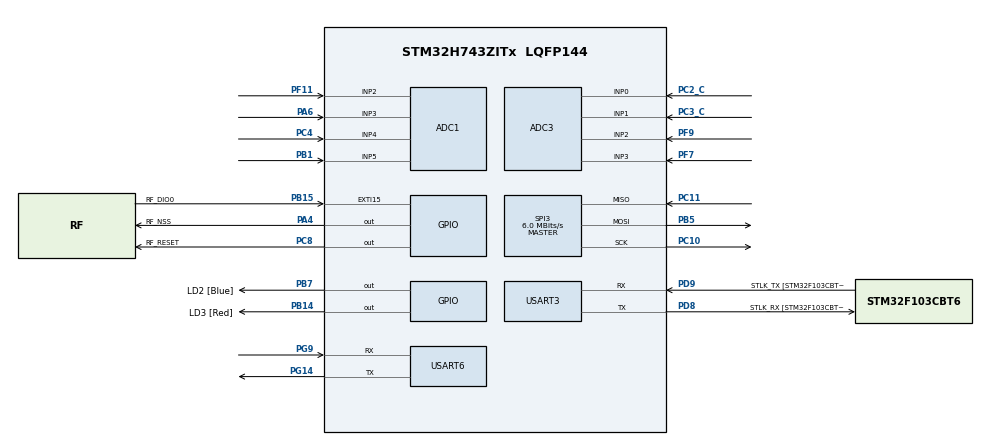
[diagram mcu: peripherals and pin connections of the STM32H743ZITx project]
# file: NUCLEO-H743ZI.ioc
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ADC1.Channel-2\#ChannelRegularConversion=ADC_CHANNEL_2
ADC1.NbrOfConversionFlag=1
ADC1.OffsetNumber-2\#ChannelRegularConversion=ADC_OFFSET_NONE
ADC1.Rank-2\#ChannelRegularConversion=1
ADC1.SamplingTime-2\#ChannelRegularConversion=ADC_SAMPLETIME_1CYCLE_5
ADC1.master=1
ADC3.Channel-0\#ChannelRegularConversion=ADC_CHANNEL_0
ADC3.NbrOfConversionFlag=1
ADC3.OffsetNumber-0\#ChannelRegularConversion=ADC_OFFSET_NONE
ADC3.Rank-0\#ChannelRegularConversion=1
ADC3.SamplingTime-0\#ChannelRegularConversion=ADC_SAMPLETIME_1CYCLE_5
FREERTOS.Tasks01=defaultTask,0,512,MAIN_taskEntry,As weak,NULL,Dynamic,NULL,NULL
FREERTOS.configMINIMAL_STACK_SIZE=256
FREERTOS.configTOTAL_HEAP_SIZE=32768
FREERTOS.configUSE_TIMERS=1
Mcu.Family=STM32H7
Mcu.Name=STM32H743ZITx
Mcu.Package=LQFP144
NVIC.EXTI15_10_IRQn=true\:5\:0\:false\:false\:true\:true\:true\:true
NVIC.PriorityGroup=NVIC_PRIORITYGROUP_4
NVIC.TIM1_UP_IRQn=true\:0\:0\:false\:false\:true\:false\:false\:true
NVIC.TimeBase=TIM1_UP_IRQn
NVIC.TimeBaseIP=TIM1
PA13\ (JTMS/SWDIO).GPIO_Label=TMS
PA13\ (JTMS/SWDIO).Mode=Serial_Wire
PA13\ (JTMS/SWDIO).Signal=SYS_JTMS-SWDIO
PA14\ (JTCK/SWCLK).GPIO_Label=TCK
PA14\ (JTCK/SWCLK).Mode=Serial_Wire
PA14\ (JTCK/SWCLK).Signal=SYS_JTCK-SWCLK
PA4.GPIO_Label=RF_NSS
PA4.Signal=GPIO_Output
PA6.Signal=ADCx_INP3
PB1.Signal=ADCx_INP5
PB14.GPIO_Label=LD3 [Red]
PB14.Signal=GPIO_Output
PB15.GPIO_Label=RF_DIO0
PB15.Signal=GPXTI15
PB3\ (JTDO/TRACESWO).Signal=SYS_JTDO-SWO
PB5.Mode=Full_Duplex_Master
PB5.Signal=SPI3_MOSI
PB7.GPIO_Label=LD2 [Blue]
PB7.Signal=GPIO_Output
PC10.Mode=Full_Duplex_Master
PC10.Signal=SPI3_SCK
PC11.Mode=Full_Duplex_Master
PC11.Signal=SPI3_MISO
PC14-OSC32_IN\ (OSC32_IN).Mode=LSE-External-Oscillator
PC14-OSC32_IN\ (OSC32_IN).Signal=RCC_OSC32_IN
PC15-OSC32_OUT\ (OSC32_OUT).Mode=LSE-External-Oscillator
PC15-OSC32_OUT\ (OSC32_OUT).Signal=RCC_OSC32_OUT
PC2_C.Mode=IN0-Single-Ended
PC2_C.Signal=ADC3_INP0
PC3_C.Mode=IN1-Single-Ended
PC3_C.Signal=ADC3_INP1
PC4.Signal=ADCx_INP4
PC8.GPIO_Label=RF_RESET
PC8.Signal=GPIO_Output
PD8.GPIO_Label=STLK_RX [STM32F103CBT6_PA3]
PD8.Mode=Asynchronous
PD8.Signal=USART3_TX
PD9.GPIO_Label=STLK_TX [STM32F103CBT6_PA2]
PD9.Mode=Asynchronous
PD9.Signal=USART3_RX
PF11.Mode=IN2-Single-Ended
PF11.Signal=ADC1_INP2
PF7.Mode=IN3-Single-Ended
PF7.Signal=ADC3_INP3
PF9.Mode=IN2-Single-Ended
PF9.Signal=ADC3_INP2
PG14.Mode=Asynchronous
PG14.Signal=USART6_TX
PG9.Mode=Asynchronous
PG9.Signal=USART6_RX
PH0-OSC_IN\ (PH0).GPIO_Label=MCO
PH0-OSC_IN\ (PH0).Mode=HSE-External-Clock-Source
PH0-OSC_IN\ (PH0).Signal=RCC_OSC_IN
PH1-OSC_OUT\ (PH1).Mode=HSE-External-Clock-Source
PH1-OSC_OUT\ (PH1).Signal=RCC_OSC_OUT
ProjectManager.HeapSize=0x200
ProjectManager.StackSize=0x400
ProjectManager.TargetToolchain=EWARM V8
RCC.48MHZClocksFreq_Value=24000000
RCC.ADCFreq_Value=76000000
RCC.AHBFreq_Value=216000000
RCC.APB1CLKDivider=RCC_HCLK_DIV4
RCC.APB1Freq_Value=96000000
RCC.APB1TimFreq_Value=108000000
RCC.APB2CLKDivider=RCC_HCLK_DIV2
RCC.APB2Freq_Value=96000000
RCC.APB2TimFreq_Value=216000000
RCC.APB3Freq_Value=96000000
RCC.APB4Freq_Value=96000000
RCC.CortexFreq_Value=96000000
RCC.DIVM1=1
RCC.DIVM2=1
RCC.DIVN1=24
RCC.DIVN2=19
RCC.DIVQ1=4
RCC.HCLKFreq_Value=96000000
RCC.HSE_VALUE=8000000
RCC.HSI_VALUE=64000000
RCC.PLLM=25
RCC.PLLMUL=RCC_PLL_MUL9
RCC.PLLN=432
RCC.PLLQ=9
RCC.PLLSourceVirtual=RCC_PLLSOURCE_HSE
RCC.PRESCALERUSB=RCC_USBCLKSOURCE_PLL_DIV1_5
RCC.PWR_Regulator_Voltage_Scale=PWR_REGULATOR_VOLTAGE_SCALE1
RCC.SYSCLKFreq_VALUE=96000000
RCC.SYSCLKSource=RCC_SYSCLKSOURCE_PLLCLK
RCC.SYSCLKSourceVirtual=RCC_SYSCLKSOURCE_PLLCLK
RCC.USBFreq_Value=48000000
RCC.VCOOutputFreq_Value=432000000
SH.ADCx_INP3.0=ADC1_INP3,IN3-Single-Ended
SH.ADCx_INP4.0=ADC1_INP4,IN4-Single-Ended
SH.ADCx_INP5.0=ADC1_INP5,IN5-Single-Ended
SPI3.BaudRatePrescaler=SPI_BAUDRATEPRESCALER_8
SPI3.CalculateBaudRate=6.0 MBits/s
SPI3.DataSize=SPI_DATASIZE_8BIT
SPI3.Direction=SPI_DIRECTION_2LINES
SPI3.Mode=SPI_MODE_MASTER
SPI3.VirtualType=VM_MASTER
USART3.VirtualMode-Asynchronous=VM_ASYNC
USART6.VirtualMode-Asynchronous=VM_ASYNC
VP_FREERTOS_VS_CMSIS_V1.Mode=CMSIS_V1
VP_RTC_VS_RTC_Activate.Mode=RTC_Enabled
VP_SYS_VS_tim1.Mode=TIM1
VP_SYS_V_PVD_IN.Mode=Mode_PVD_Int
board=NUCLEO-H743ZI

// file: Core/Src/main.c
/* USER CODE BEGIN Header */
/**
  ******************************************************************************
  * @file           : main.c
  * @brief          : Main program body
  ******************************************************************************
  * @attention
  *
  * <h2><center>&copy; Copyright (c) 2019 STMicroelectronics.
  * All rights reserved.</center></h2>
  *
  * This software component is licensed by ST under Ultimate Liberty license
  * SLA0044, the "License"; You may not use this file except in compliance with
  * the License. You may obtain a copy of the License at:
  *                             www.st.com/SLA0044
  *
  ******************************************************************************
  */
/* USER CODE END Header */

#include "main.h"
#include "cmsis_os.h"

/* USER CODE BEGIN Includes */
#include "config.h"
/* USER CODE END Includes */

ADC_HandleTypeDef hadc1;
ADC_HandleTypeDef hadc3;

RTC_HandleTypeDef hrtc;

SPI_HandleTypeDef hspi3;

UART_HandleTypeDef huart3;
UART_HandleTypeDef huart6;

osThreadId defaultTaskHandle;
/* USER CODE BEGIN PV */
/* Private variables ---------------------------------------------------------*/

/* USER CODE END PV */

void SystemClock_Config(void);
static void MX_GPIO_Init(void);
static void MX_USART3_UART_Init(void);
static void MX_USART6_UART_Init(void);
static void MX_ADC3_Init(void);
static void MX_ADC1_Init(void);
static void MX_RTC_Init(void);
static void MX_SPI3_Init(void);
void MAIN_taskEntry(void const * argument);

/* USER CODE BEGIN PFP */
/* Private function prototypes -----------------------------------------------*/

/* USER CODE END PFP */

int main(void)
{

  /* MCU Configuration--------------------------------------------------------*/

  /* Reset of all peripherals, Initializes the Flash interface and the Systick. */
  HAL_Init();

  /* Configure the system clock */
  SystemClock_Config();

  /* Initialize all configured peripherals */
  MX_GPIO_Init();
  MX_USART3_UART_Init();
  MX_USART6_UART_Init();
  MX_ADC3_Init();
  MX_ADC1_Init();
  MX_RTC_Init();
  MX_SPI3_Init();
  /* USER CODE BEGIN 2 */
  RF_init(&hspi3);

  /* USER CODE END 2 */

  /* Create the thread(s) */
  /* definition and creation of defaultTask */
  osThreadDef(defaultTask, MAIN_taskEntry, osPriorityNormal, 0, 512);
  defaultTaskHandle = osThreadCreate(osThread(defaultTask), NULL);

  /* Start scheduler */
  osKernelStart();

  /* We should never get here as control is now taken by the scheduler */

  /* Infinite loop */
  while (1)
  {

  }
}

void SystemClock_Config(void)
{
  RCC_OscInitTypeDef RCC_OscInitStruct = {0};
  RCC_ClkInitTypeDef RCC_ClkInitStruct = {0};
  RCC_PeriphCLKInitTypeDef PeriphClkInitStruct = {0};

  /** Supply configuration update enable
  */
  MODIFY_REG(PWR->CR3, PWR_CR3_SCUEN, 0);
  /** Configure the main internal regulator output voltage
  */
  __HAL_PWR_VOLTAGESCALING_CONFIG(PWR_REGULATOR_VOLTAGE_SCALE1);

  while ((PWR->D3CR & (PWR_D3CR_VOSRDY)) != PWR_D3CR_VOSRDY)
  {

  }
  /** Macro to configure the PLL clock source
  */
  __HAL_RCC_PLL_PLLSOURCE_CONFIG(RCC_PLLSOURCE_HSE);
  /** Initializes the CPU, AHB and APB busses clocks
  */
  RCC_OscInitStruct.OscillatorType = RCC_OSCILLATORTYPE_LSI|RCC_OSCILLATORTYPE_HSE;
  RCC_OscInitStruct.HSEState = RCC_HSE_BYPASS;
  RCC_OscInitStruct.LSIState = RCC_LSI_ON;
  RCC_OscInitStruct.PLL.PLLState = RCC_PLL_ON;
  RCC_OscInitStruct.PLL.PLLSource = RCC_PLLSOURCE_HSE;
  RCC_OscInitStruct.PLL.PLLM = 1;
  RCC_OscInitStruct.PLL.PLLN = 24;
  RCC_OscInitStruct.PLL.PLLP = 2;
  RCC_OscInitStruct.PLL.PLLQ = 4;
  RCC_OscInitStruct.PLL.PLLR = 2;
  RCC_OscInitStruct.PLL.PLLRGE = RCC_PLL1VCIRANGE_3;
  RCC_OscInitStruct.PLL.PLLVCOSEL = RCC_PLL1VCOWIDE;
  RCC_OscInitStruct.PLL.PLLFRACN = 0;
  if (HAL_RCC_OscConfig(&RCC_OscInitStruct) != HAL_OK)
  {
    Error_Handler();
  }
  /** Initializes the CPU, AHB and APB busses clocks
  */
  RCC_ClkInitStruct.ClockType = RCC_CLOCKTYPE_HCLK|RCC_CLOCKTYPE_SYSCLK
                              |RCC_CLOCKTYPE_PCLK1|RCC_CLOCKTYPE_PCLK2
                              |RCC_CLOCKTYPE_D3PCLK1|RCC_CLOCKTYPE_D1PCLK1;
  RCC_ClkInitStruct.SYSCLKSource = RCC_SYSCLKSOURCE_PLLCLK;
  RCC_ClkInitStruct.SYSCLKDivider = RCC_SYSCLK_DIV1;
  RCC_ClkInitStruct.AHBCLKDivider = RCC_HCLK_DIV1;
  RCC_ClkInitStruct.APB3CLKDivider = RCC_APB3_DIV1;
  RCC_ClkInitStruct.APB1CLKDivider = RCC_APB1_DIV1;
  RCC_ClkInitStruct.APB2CLKDivider = RCC_APB2_DIV1;
  RCC_ClkInitStruct.APB4CLKDivider = RCC_APB4_DIV1;

  if (HAL_RCC_ClockConfig(&RCC_ClkInitStruct, FLASH_LATENCY_1) != HAL_OK)
  {
    Error_Handler();
  }
  PeriphClkInitStruct.PeriphClockSelection = RCC_PERIPHCLK_RTC|RCC_PERIPHCLK_USART3
                              |RCC_PERIPHCLK_USART6|RCC_PERIPHCLK_SPI3
                              |RCC_PERIPHCLK_ADC;
  PeriphClkInitStruct.PLL2.PLL2M = 1;
  PeriphClkInitStruct.PLL2.PLL2N = 19;
  PeriphClkInitStruct.PLL2.PLL2P = 2;
  PeriphClkInitStruct.PLL2.PLL2Q = 2;
  PeriphClkInitStruct.PLL2.PLL2R = 2;
  PeriphClkInitStruct.PLL2.PLL2RGE = RCC_PLL2VCIRANGE_3;
  PeriphClkInitStruct.PLL2.PLL2VCOSEL = RCC_PLL2VCOMEDIUM;
  PeriphClkInitStruct.PLL2.PLL2FRACN = 0;
  PeriphClkInitStruct.Spi123ClockSelection = RCC_SPI123CLKSOURCE_PLL;
  PeriphClkInitStruct.Usart234578ClockSelection = RCC_USART234578CLKSOURCE_D2PCLK1;
  PeriphClkInitStruct.Usart16ClockSelection = RCC_USART16CLKSOURCE_D2PCLK2;
  PeriphClkInitStruct.AdcClockSelection = RCC_ADCCLKSOURCE_PLL2;
  PeriphClkInitStruct.RTCClockSelection = RCC_RTCCLKSOURCE_LSI;
  if (HAL_RCCEx_PeriphCLKConfig(&PeriphClkInitStruct) != HAL_OK)
  {
    Error_Handler();
  }
}

static void MX_ADC1_Init(void)
{

  ADC_MultiModeTypeDef multimode = {0};
  ADC_ChannelConfTypeDef sConfig = {0};

  /** Common config
  */
  hadc1.Instance = ADC1;
  hadc1.Init.ClockPrescaler = ADC_CLOCK_ASYNC_DIV4;
  hadc1.Init.Resolution = ADC_RESOLUTION_16B;
  hadc1.Init.ScanConvMode = ADC_SCAN_DISABLE;
  hadc1.Init.EOCSelection = ADC_EOC_SINGLE_CONV;
  hadc1.Init.LowPowerAutoWait = DISABLE;
  hadc1.Init.ContinuousConvMode = DISABLE;
  hadc1.Init.NbrOfConversion = 1;
  hadc1.Init.DiscontinuousConvMode = DISABLE;
  hadc1.Init.ExternalTrigConv = ADC_SOFTWARE_START;
  hadc1.Init.ExternalTrigConvEdge = ADC_EXTERNALTRIGCONVEDGE_NONE;
  hadc1.Init.ConversionDataManagement = ADC_CONVERSIONDATA_DR;
  hadc1.Init.Overrun = ADC_OVR_DATA_PRESERVED;
  hadc1.Init.LeftBitShift = ADC_LEFTBITSHIFT_NONE;
  hadc1.Init.BoostMode = DISABLE;
  hadc1.Init.OversamplingMode = DISABLE;
  if (HAL_ADC_Init(&hadc1) != HAL_OK)
  {
    Error_Handler();
  }
  /** Configure the ADC multi-mode
  */
  multimode.Mode = ADC_MODE_INDEPENDENT;
  if (HAL_ADCEx_MultiModeConfigChannel(&hadc1, &multimode) != HAL_OK)
  {
    Error_Handler();
  }
  /** Configure Regular Channel
  */
  sConfig.Channel = ADC_CHANNEL_2;
  sConfig.Rank = ADC_REGULAR_RANK_1;
  sConfig.SamplingTime = ADC_SAMPLETIME_1CYCLE_5;
  sConfig.SingleDiff = ADC_SINGLE_ENDED;
  sConfig.OffsetNumber = ADC_OFFSET_NONE;
  sConfig.Offset = 0;
  if (HAL_ADC_ConfigChannel(&hadc1, &sConfig) != HAL_OK)
  {
    Error_Handler();
  }

}

static void MX_ADC3_Init(void)
{

  ADC_ChannelConfTypeDef sConfig = {0};

  /** Common config
  */
  hadc3.Instance = ADC3;
  hadc3.Init.ClockPrescaler = ADC_CLOCK_ASYNC_DIV4;
  hadc3.Init.Resolution = ADC_RESOLUTION_16B;
  hadc3.Init.ScanConvMode = ADC_SCAN_DISABLE;
  hadc3.Init.EOCSelection = ADC_EOC_SINGLE_CONV;
  hadc3.Init.LowPowerAutoWait = DISABLE;
  hadc3.Init.ContinuousConvMode = DISABLE;
  hadc3.Init.NbrOfConversion = 1;
  hadc3.Init.DiscontinuousConvMode = DISABLE;
  hadc3.Init.ExternalTrigConv = ADC_SOFTWARE_START;
  hadc3.Init.ExternalTrigConvEdge = ADC_EXTERNALTRIGCONVEDGE_NONE;
  hadc3.Init.ConversionDataManagement = ADC_CONVERSIONDATA_DR;
  hadc3.Init.Overrun = ADC_OVR_DATA_PRESERVED;
  hadc3.Init.LeftBitShift = ADC_LEFTBITSHIFT_NONE;
  hadc3.Init.BoostMode = DISABLE;
  hadc3.Init.OversamplingMode = DISABLE;
  if (HAL_ADC_Init(&hadc3) != HAL_OK)
  {
    Error_Handler();
  }
  /** Configure Regular Channel
  */
  sConfig.Channel = ADC_CHANNEL_0;
  sConfig.Rank = ADC_REGULAR_RANK_1;
  sConfig.SamplingTime = ADC_SAMPLETIME_1CYCLE_5;
  sConfig.SingleDiff = ADC_SINGLE_ENDED;
  sConfig.OffsetNumber = ADC_OFFSET_NONE;
  sConfig.Offset = 0;
  if (HAL_ADC_ConfigChannel(&hadc3, &sConfig) != HAL_OK)
  {
    Error_Handler();
  }

}

static void MX_RTC_Init(void)
{

  /** Initialize RTC Only
  */
  hrtc.Instance = RTC;
  hrtc.Init.HourFormat = RTC_HOURFORMAT_24;
  hrtc.Init.AsynchPrediv = 127;
  hrtc.Init.SynchPrediv = 255;
  hrtc.Init.OutPut = RTC_OUTPUT_DISABLE;
  hrtc.Init.OutPutPolarity = RTC_OUTPUT_POLARITY_HIGH;
  hrtc.Init.OutPutType = RTC_OUTPUT_TYPE_OPENDRAIN;
  hrtc.Init.OutPutRemap = RTC_OUTPUT_REMAP_NONE;
  if (HAL_RTC_Init(&hrtc) != HAL_OK)
  {
    Error_Handler();
  }

}

static void MX_SPI3_Init(void)
{

  /* SPI3 parameter configuration*/
  hspi3.Instance = SPI3;
  hspi3.Init.Mode = SPI_MODE_MASTER;
  hspi3.Init.Direction = SPI_DIRECTION_2LINES;
  hspi3.Init.DataSize = SPI_DATASIZE_8BIT;
  hspi3.Init.CLKPolarity = SPI_POLARITY_LOW;
  hspi3.Init.CLKPhase = SPI_PHASE_1EDGE;
  hspi3.Init.NSS = SPI_NSS_SOFT;
  hspi3.Init.BaudRatePrescaler = SPI_BAUDRATEPRESCALER_8;
  hspi3.Init.FirstBit = SPI_FIRSTBIT_MSB;
  hspi3.Init.TIMode = SPI_TIMODE_DISABLE;
  hspi3.Init.CRCCalculation = SPI_CRCCALCULATION_DISABLE;
  hspi3.Init.CRCPolynomial = 7;
  hspi3.Init.NSSPMode = SPI_NSS_PULSE_ENABLE;
  hspi3.Init.NSSPolarity = SPI_NSS_POLARITY_LOW;
  hspi3.Init.FifoThreshold = SPI_FIFO_THRESHOLD_01DATA;
  hspi3.Init.TxCRCInitializationPattern = SPI_CRC_INITIALIZATION_ALL_ZERO_PATTERN;
  hspi3.Init.RxCRCInitializationPattern = SPI_CRC_INITIALIZATION_ALL_ZERO_PATTERN;
  hspi3.Init.MasterSSIdleness = SPI_MASTER_SS_IDLENESS_00CYCLE;
  hspi3.Init.MasterInterDataIdleness = SPI_MASTER_INTERDATA_IDLENESS_00CYCLE;
  hspi3.Init.MasterReceiverAutoSusp = SPI_MASTER_RX_AUTOSUSP_DISABLE;
  hspi3.Init.MasterKeepIOState = SPI_MASTER_KEEP_IO_STATE_DISABLE;
  hspi3.Init.IOSwap = SPI_IO_SWAP_DISABLE;
  if (HAL_SPI_Init(&hspi3) != HAL_OK)
  {
    Error_Handler();
  }

}

static void MX_USART3_UART_Init(void)
{

  huart3.Instance = USART3;
  huart3.Init.BaudRate = 115200;
  huart3.Init.WordLength = UART_WORDLENGTH_8B;
  huart3.Init.StopBits = UART_STOPBITS_1;
  huart3.Init.Parity = UART_PARITY_NONE;
  huart3.Init.Mode = UART_MODE_TX_RX;
  huart3.Init.HwFlowCtl = UART_HWCONTROL_NONE;
  huart3.Init.OverSampling = UART_OVERSAMPLING_16;
  huart3.Init.OneBitSampling = UART_ONE_BIT_SAMPLE_DISABLE;
  huart3.Init.Prescaler = UART_PRESCALER_DIV1;
  huart3.Init.FIFOMode = UART_FIFOMODE_DISABLE;
  huart3.Init.TXFIFOThreshold = UART_TXFIFO_THRESHOLD_1_8;
  huart3.Init.RXFIFOThreshold = UART_RXFIFO_THRESHOLD_1_8;
  huart3.AdvancedInit.AdvFeatureInit = UART_ADVFEATURE_NO_INIT;
  if (HAL_UART_Init(&huart3) != HAL_OK)
  {
    Error_Handler();
  }

}

static void MX_USART6_UART_Init(void)
{

  huart6.Instance = USART6;
  huart6.Init.BaudRate = 115200;
  huart6.Init.WordLength = UART_WORDLENGTH_8B;
  huart6.Init.StopBits = UART_STOPBITS_1;
  huart6.Init.Parity = UART_PARITY_NONE;
  huart6.Init.Mode = UART_MODE_TX_RX;
  huart6.Init.HwFlowCtl = UART_HWCONTROL_NONE;
  huart6.Init.OverSampling = UART_OVERSAMPLING_16;
  huart6.Init.OneBitSampling = UART_ONE_BIT_SAMPLE_DISABLE;
  huart6.Init.Prescaler = UART_PRESCALER_DIV1;
  huart6.Init.FIFOMode = UART_FIFOMODE_DISABLE;
  huart6.Init.TXFIFOThreshold = UART_TXFIFO_THRESHOLD_1_8;
  huart6.Init.RXFIFOThreshold = UART_RXFIFO_THRESHOLD_1_8;
  huart6.AdvancedInit.AdvFeatureInit = UART_ADVFEATURE_NO_INIT;
  if (HAL_UART_Init(&huart6) != HAL_OK)
  {
    Error_Handler();
  }

}

static void MX_GPIO_Init(void)
{
  GPIO_InitTypeDef GPIO_InitStruct = {0};

  /* GPIO Ports Clock Enable */
  __HAL_RCC_GPIOC_CLK_ENABLE();
  __HAL_RCC_GPIOF_CLK_ENABLE();
  __HAL_RCC_GPIOH_CLK_ENABLE();
  __HAL_RCC_GPIOA_CLK_ENABLE();
  __HAL_RCC_GPIOB_CLK_ENABLE();
  __HAL_RCC_GPIOD_CLK_ENABLE();
  __HAL_RCC_GPIOG_CLK_ENABLE();

  /*Configure GPIO pin Output Level */
  HAL_GPIO_WritePin(RF_NSS_GPIO_Port, RF_NSS_Pin, GPIO_PIN_RESET);

  /*Configure GPIO pin Output Level */
  HAL_GPIO_WritePin(GPIOB, LD3_Pin|LD2_Pin, GPIO_PIN_RESET);

  /*Configure GPIO pin Output Level */
  HAL_GPIO_WritePin(RF_RESET_GPIO_Port, RF_RESET_Pin, GPIO_PIN_RESET);

  /*Configure GPIO pin : RF_NSS_Pin */
  GPIO_InitStruct.Pin = RF_NSS_Pin;
  GPIO_InitStruct.Mode = GPIO_MODE_OUTPUT_PP;
  GPIO_InitStruct.Pull = GPIO_NOPULL;
  GPIO_InitStruct.Speed = GPIO_SPEED_FREQ_LOW;
  HAL_GPIO_Init(RF_NSS_GPIO_Port, &GPIO_InitStruct);

  /*Configure GPIO pins : LD3_Pin LD2_Pin */
  GPIO_InitStruct.Pin = LD3_Pin|LD2_Pin;
  GPIO_InitStruct.Mode = GPIO_MODE_OUTPUT_PP;
  GPIO_InitStruct.Pull = GPIO_NOPULL;
  GPIO_InitStruct.Speed = GPIO_SPEED_FREQ_LOW;
  HAL_GPIO_Init(GPIOB, &GPIO_InitStruct);

  /*Configure GPIO pin : RF_DIO0_Pin */
  GPIO_InitStruct.Pin = RF_DIO0_Pin;
  GPIO_InitStruct.Mode = GPIO_MODE_IT_RISING;
  GPIO_InitStruct.Pull = GPIO_NOPULL;
  HAL_GPIO_Init(RF_DIO0_GPIO_Port, &GPIO_InitStruct);

  /*Configure GPIO pin : RF_RESET_Pin */
  GPIO_InitStruct.Pin = RF_RESET_Pin;
  GPIO_InitStruct.Mode = GPIO_MODE_OUTPUT_PP;
  GPIO_InitStruct.Pull = GPIO_NOPULL;
  GPIO_InitStruct.Speed = GPIO_SPEED_FREQ_LOW;
  HAL_GPIO_Init(RF_RESET_GPIO_Port, &GPIO_InitStruct);

  /* EXTI interrupt init*/
  HAL_NVIC_SetPriority(EXTI15_10_IRQn, 5, 0);
  HAL_NVIC_EnableIRQ(EXTI15_10_IRQn);

}

__weak void MAIN_taskEntry(void const * argument)
{

}

void HAL_TIM_PeriodElapsedCallback(TIM_HandleTypeDef *htim)
{
  if (htim->Instance == TIM1) {
    HAL_IncTick();
  }
}

void Error_Handler(void)
{
  while(1)
  {
  }
}

/************************ (C) COPYRIGHT STMicroelectronics *****END OF FILE****/
